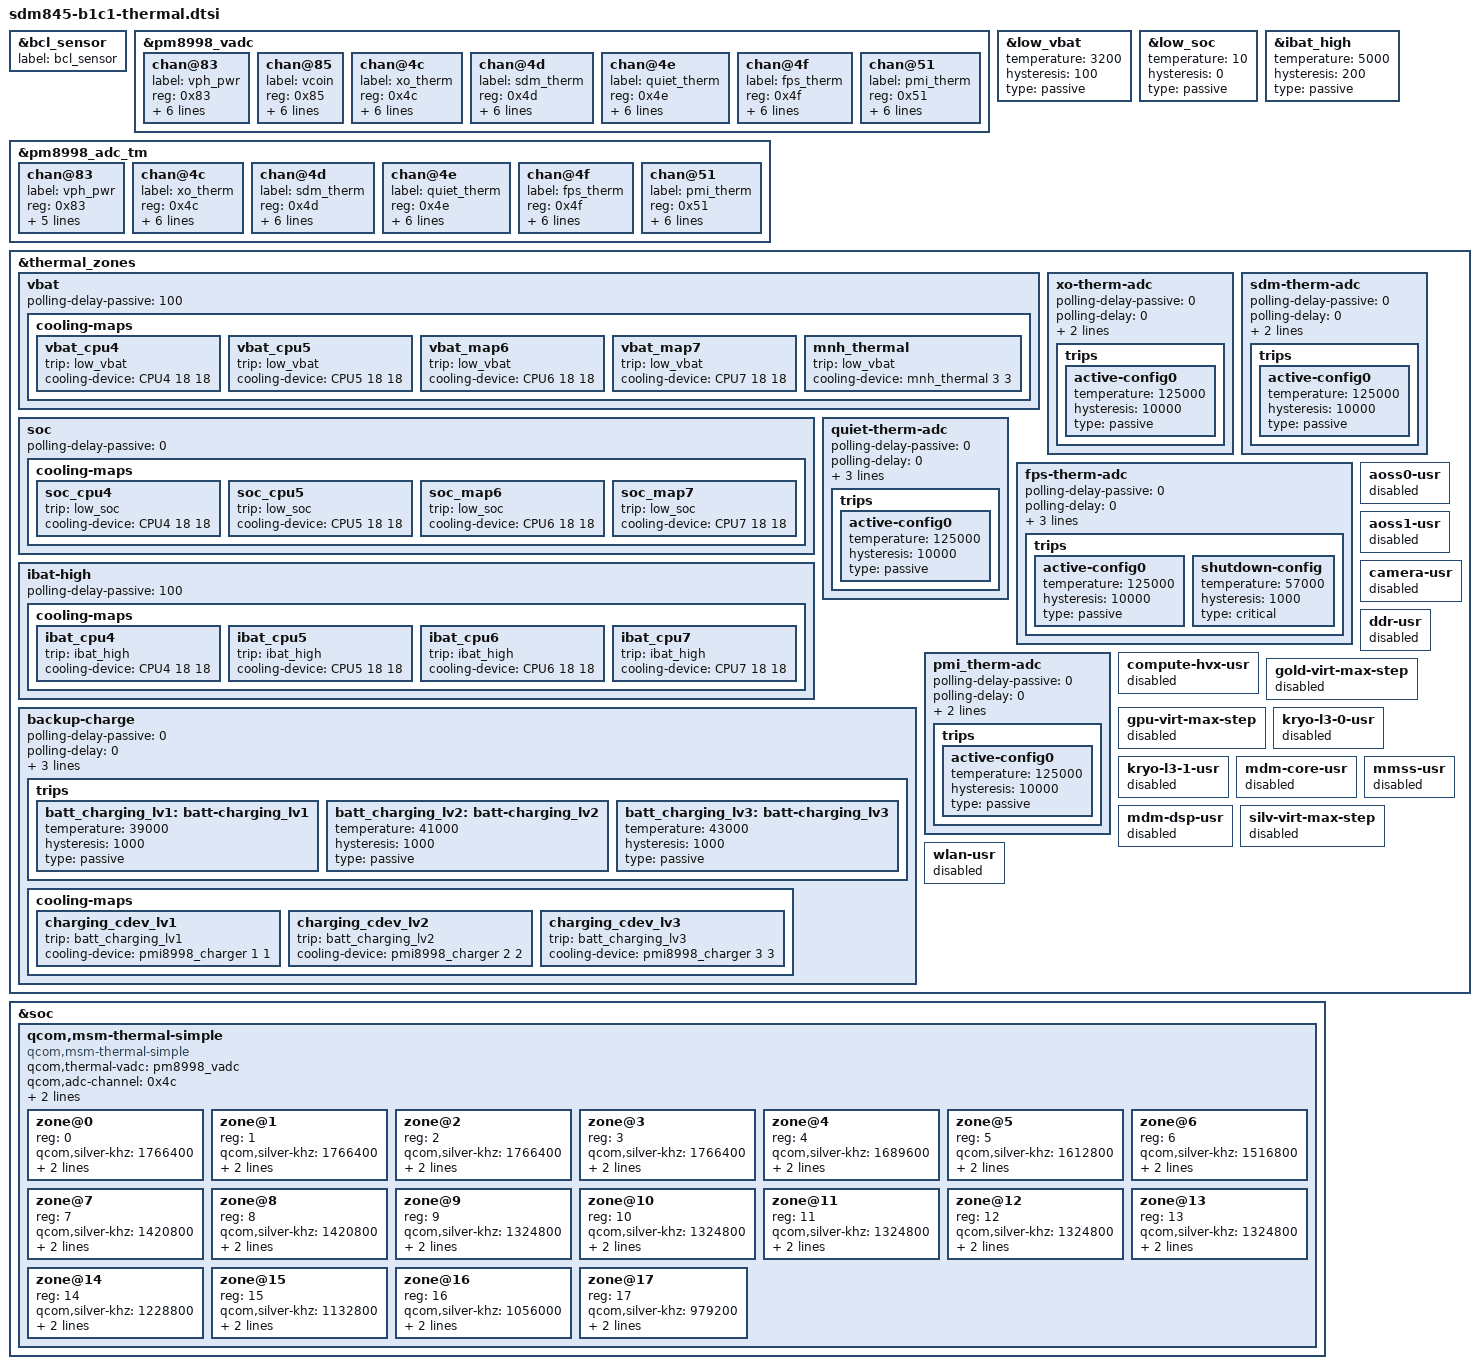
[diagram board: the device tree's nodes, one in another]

&bcl_sensor {
	label = "bcl_sensor";
};

&pm8998_vadc {
	chan@83 {
		label = "vph_pwr";
		reg = <0x83>;
		qcom,decimation = <2>;
		qcom,pre-div-channel-scaling = <1>;
		qcom,calibration-type = "absolute";
		qcom,scale-function = <0>;
		qcom,hw-settle-time = <0>;
		qcom,fast-avg-setup = <0>;
	};

	chan@85 {
		label = "vcoin";
		reg = <0x85>;
		qcom,decimation = <2>;
		qcom,pre-div-channel-scaling = <1>;
		qcom,calibration-type = "absolute";
		qcom,scale-function = <0>;
		qcom,hw-settle-time = <0>;
		qcom,fast-avg-setup = <0>;
	};

	chan@4c {
		label = "xo_therm";
		reg = <0x4c>;
		qcom,decimation = <2>;
		qcom,pre-div-channel-scaling = <0>;
		qcom,calibration-type = "ratiometric";
		qcom,scale-function = <4>;
		qcom,hw-settle-time = <2>;
		qcom,fast-avg-setup = <0>;
	};

	chan@4d {
		label = "sdm_therm";
		reg = <0x4d>;
		qcom,decimation = <2>;
		qcom,pre-div-channel-scaling = <0>;
		qcom,calibration-type = "ratiometric";
		qcom,scale-function = <2>;
		qcom,hw-settle-time = <2>;
		qcom,fast-avg-setup = <0>;
	};

	chan@4e {
		label = "quiet_therm";
		reg = <0x4e>;
		qcom,decimation = <2>;
		qcom,pre-div-channel-scaling = <0>;
		qcom,calibration-type = "ratiometric";
		qcom,scale-function = <2>;
		qcom,hw-settle-time = <2>;
		qcom,fast-avg-setup = <0>;
	};

	chan@4f {
		label = "fps_therm";
		reg = <0x4f>;
		qcom,decimation = <2>;
		qcom,pre-div-channel-scaling = <0>;
		qcom,calibration-type = "ratiometric";
		qcom,scale-function = <2>;
		qcom,hw-settle-time = <2>;
		qcom,fast-avg-setup = <0>;
	};

	chan@51 {
		label = "pmi_therm";
		reg = <0x51>;
		qcom,decimation = <2>;
		qcom,pre-div-channel-scaling = <0>;
		qcom,calibration-type = "ratiometric";
		qcom,scale-function = <2>;
		qcom,hw-settle-time = <2>;
		qcom,fast-avg-setup = <0>;
	};
};

&pm8998_adc_tm {
	chan@83 {
		label = "vph_pwr";
		reg = <0x83>;
		qcom,pre-div-channel-scaling = <1>;
		qcom,calibration-type = "absolute";
		qcom,scale-function = <0>;
		qcom,hw-settle-time = <0>;
		qcom,btm-channel-number = <0x60>;
	};

	chan@4c {
		label = "xo_therm";
		reg = <0x4c>;
		qcom,pre-div-channel-scaling = <0>;
		qcom,calibration-type = "ratiometric";
		qcom,scale-function = <4>;
		qcom,hw-settle-time = <2>;
		qcom,btm-channel-number = <0x68>;
		qcom,thermal-node;
	};

	chan@4d {
		label = "sdm_therm";
		reg = <0x4d>;
		qcom,pre-div-channel-scaling = <0>;
		qcom,calibration-type = "ratiometric";
		qcom,scale-function = <2>;
		qcom,hw-settle-time = <2>;
		qcom,btm-channel-number = <0x70>;
		qcom,thermal-node;
	};

	chan@4e {
		label = "quiet_therm";
		reg = <0x4e>;
		qcom,pre-div-channel-scaling = <0>;
		qcom,calibration-type = "ratiometric";
		qcom,scale-function = <2>;
		qcom,hw-settle-time = <2>;
		qcom,btm-channel-number = <0x78>;
		qcom,thermal-node;
	};

	chan@4f {
		label = "fps_therm";
		reg = <0x4f>;
		qcom,pre-div-channel-scaling = <0>;
		qcom,calibration-type = "ratiometric";
		qcom,scale-function = <2>;
		qcom,hw-settle-time = <2>;
		qcom,btm-channel-number = <0x98>;
		qcom,thermal-node;
	};

	chan@51 {
		label = "pmi_therm";
		reg = <0x51>;
		qcom,pre-div-channel-scaling = <0>;
		qcom,calibration-type = "ratiometric";
		qcom,scale-function = <2>;
		qcom,hw-settle-time = <2>;
		qcom,btm-channel-number = <0x88>;
		qcom,thermal-node;
	};
};

&low_vbat {
	temperature = <3200>;
	hysteresis = <100>;
	type = "passive";
};

&low_soc {
	temperature = <10>;
	hysteresis = <0>;
	type = "passive";
};

&ibat_high {
	temperature = <5000>;
	hysteresis = <200>;
	type = "passive";
};

&thermal_zones {
	vbat {
		polling-delay-passive = <100>;
		cooling-maps {
			vbat_cpu4 {
				trip = <&low_vbat>;
				cooling-device =
					<&CPU4 18 18>;
			};
			vbat_cpu5 {
				trip = <&low_vbat>;
				cooling-device =
					<&CPU5 18 18>;
			};
			vbat_map6 {
				trip = <&low_vbat>;
				cooling-device =
					<&CPU6 18 18>;
			};
			vbat_map7 {
				trip = <&low_vbat>;
				cooling-device =
					<&CPU7 18 18>;
			};
			mnh_thermal {
				trip = <&low_vbat>;
				cooling-device =
					<&mnh_thermal 3 3>;
			};
		};
	};
	soc {
		polling-delay-passive = <0>;
		cooling-maps {
			soc_cpu4 {
				trip = <&low_soc>;
				cooling-device =
					<&CPU4 18 18>;
			};
			soc_cpu5 {
				trip = <&low_soc>;
				cooling-device =
					<&CPU5 18 18>;
			};
			soc_map6 {
				trip = <&low_soc>;
				cooling-device =
					<&CPU6 18 18>;
			};
			soc_map7 {
				trip = <&low_soc>;
				cooling-device =
					<&CPU7 18 18>;
			};
		};
	};
	ibat-high {
		polling-delay-passive = <100>;
		cooling-maps {
			ibat_cpu4 {
				trip = <&ibat_high>;
				cooling-device =
					<&CPU4 18 18>;
			};
			ibat_cpu5 {
				trip = <&ibat_high>;
				cooling-device =
					<&CPU5 18 18>;
			};
			ibat_cpu6 {
				trip = <&ibat_high>;
				cooling-device =
					<&CPU6 18 18>;
			};
			ibat_cpu7 {
				trip = <&ibat_high>;
				cooling-device =
					<&CPU7 18 18>;
			};
		};
	};

	xo-therm-adc {
		polling-delay-passive = <0>;
		polling-delay = <0>;
		thermal-sensors = <&pm8998_adc_tm 0x4c>;
		thermal-governor = "user_space";

		trips {
			active-config0 {
				temperature = <125000>;
				hysteresis = <10000>;
				type = "passive";
			};
		};
	};

	sdm-therm-adc {
		polling-delay-passive = <0>;
		polling-delay = <0>;
		thermal-sensors = <&pm8998_adc_tm 0x4d>;
		thermal-governor = "user_space";

		trips {
			active-config0 {
				temperature = <125000>;
				hysteresis = <10000>;
				type = "passive";
			};
		};
	};

	quiet-therm-adc {
		polling-delay-passive = <0>;
		polling-delay = <0>;
		thermal-sensors = <&pm8998_adc_tm 0x4e>;
		thermal-governor = "user_space";
		disable-thermal-zone;

		trips {
			active-config0 {
				temperature = <125000>;
				hysteresis = <10000>;
				type = "passive";
			};
		};
	};

	backup-charge {
		polling-delay-passive = <0>;
		polling-delay = <0>;
		thermal-sensors = <&pm8998_adc_tm 0x4f>;
		thermal-governor = "step_wise";
		disable-thermal-zone;

		trips {
			batt_charging_lv1: batt-charging_lv1 {
				temperature = <39000>;
				hysteresis = <1000>;
				type = "passive";
			};
			batt_charging_lv2: batt-charging_lv2 {
				temperature = <41000>;
				hysteresis = <1000>;
				type = "passive";
			};
			batt_charging_lv3: batt-charging_lv3 {
				temperature = <43000>;
				hysteresis = <1000>;
				type = "passive";
			};
		};
		cooling-maps {
			charging_cdev_lv1 {
				trip = <&batt_charging_lv1>;
				cooling-device = <&pmi8998_charger 1 1>;
			};
			charging_cdev_lv2 {
				trip = <&batt_charging_lv2>;
				cooling-device = <&pmi8998_charger 2 2>;
			};
			charging_cdev_lv3 {
				trip = <&batt_charging_lv3>;
				cooling-device = <&pmi8998_charger 3 3>;
			};
		};
	};

	fps-therm-adc {
		polling-delay-passive = <0>;
		polling-delay = <0>;
		thermal-sensors = <&pm8998_adc_tm 0x4f>;
		thermal-governor = "user_space";
		disable-thermal-zone;

		trips {
			active-config0 {
				temperature = <125000>;
				hysteresis = <10000>;
				type = "passive";
			};
			shutdown-config {
				temperature = <57000>;
				hysteresis = <1000>;
				type = "critical";
			};
		};
	};

	pmi_therm-adc {
		polling-delay-passive = <0>;
		polling-delay = <0>;
		thermal-sensors = <&pm8998_adc_tm 0x51>;
		thermal-governor = "user_space";

		trips {
			active-config0 {
				temperature = <125000>;
				hysteresis = <10000>;
				type = "passive";
			};
		};
	};

	aoss0-usr {
		status = "disabled";
	};

	aoss1-usr {
		status = "disabled";
	};

	camera-usr {
		status = "disabled";
	};

	compute-hvx-usr {
		status = "disabled";
	};

	ddr-usr {
		status = "disabled";
	};

	gold-virt-max-step {
		status = "disabled";
	};

	gpu-virt-max-step {
		status = "disabled";
	};

	kryo-l3-0-usr {
		status = "disabled";
	};

	kryo-l3-1-usr {
		status = "disabled";
	};

	mdm-core-usr {
		status = "disabled";
	};

	mdm-dsp-usr {
		status = "disabled";
	};

	mmss-usr {
		status = "disabled";
	};

	silv-virt-max-step {
		status = "disabled";
	};

	wlan-usr {
		status = "disabled";
	};
};

&soc {
	qcom,msm-thermal-simple {
		compatible = "qcom,msm-thermal-simple";
		qcom,thermal-vadc = <&pm8998_vadc>;
		qcom,adc-channel = <0x4c>;
		qcom,poll-ms = <3000>;
		qcom,start-delay = <60>;

		zone@0 {
			reg = <0>;
			qcom,silver-khz = <1766400>;
			qcom,gold-khz = <2246400>;
			qcom,trip-deg = <40000>;
		};

		zone@1 {
			reg = <1>;
			qcom,silver-khz = <1766400>;
			qcom,gold-khz = <2169600>;
			qcom,trip-deg = <41500>;
		};

		zone@2 {
			reg = <2>;
			qcom,silver-khz = <1766400>;
			qcom,gold-khz = <2092800>;
			qcom,trip-deg = <43000>;
		};

		zone@3 {
			reg = <3>;
			qcom,silver-khz = <1766400>;
			qcom,gold-khz = <1996800>;
			qcom,trip-deg = <44500>;
		};

		zone@4 {
			reg = <4>;
			qcom,silver-khz = <1689600>;
			qcom,gold-khz = <1920000>;
			qcom,trip-deg = <46000>;
		};

		zone@5 {
			reg = <5>;
			qcom,silver-khz = <1612800>;
			qcom,gold-khz = <1843200>;
			qcom,trip-deg = <47500>;
		};

		zone@6 {
			reg = <6>;
			qcom,silver-khz = <1516800>;
			qcom,gold-khz = <1766400>;
			qcom,trip-deg = <49000>;
		};

		zone@7 {
			reg = <7>;
			qcom,silver-khz = <1420800>;
			qcom,gold-khz = <1689600>;
			qcom,trip-deg = <50500>;
		};

		zone@8 {
			reg = <8>;
			qcom,silver-khz = <1420800>;
			qcom,gold-khz = <1612800>;
			qcom,trip-deg = <52000>;
		};

		zone@9 {
			reg = <9>;
			qcom,silver-khz = <1324800>;
			qcom,gold-khz = <1536000>;
			qcom,trip-deg = <53500>;
		};

		zone@10 {
			reg = <10>;
			qcom,silver-khz = <1324800>;
			qcom,gold-khz = <1459200>;
			qcom,trip-deg = <55000>;
		};

		zone@11 {
			reg = <11>;
			qcom,silver-khz = <1324800>;
			qcom,gold-khz = <1363200>;
			qcom,trip-deg = <56000>;
		};

		zone@12 {
			reg = <12>;
			qcom,silver-khz = <1324800>;
			qcom,gold-khz = <1286400>;
			qcom,trip-deg = <57000>;
		};

		zone@13 {
			reg = <13>;
			qcom,silver-khz = <1324800>;
			qcom,gold-khz = <1209600>;
			qcom,trip-deg = <58000>;
		};

		zone@14 {
			reg = <14>;
			qcom,silver-khz = <1228800>;
			qcom,gold-khz = <1056000>;
			qcom,trip-deg = <59000>;
		};

		zone@15 {
			reg = <15>;
			qcom,silver-khz = <1132800>;
			qcom,gold-khz = <979200>;
			qcom,trip-deg = <60000>;
		};

		zone@16 {
			reg = <16>;
			qcom,silver-khz = <1056000>;
			qcom,gold-khz = <902400>;
			qcom,trip-deg = <65000>;
		};

		zone@17 {
			reg = <17>;
			qcom,silver-khz = <979200>;
			qcom,gold-khz = <825600>;
			qcom,trip-deg = <70000>;
		};
	};
};
